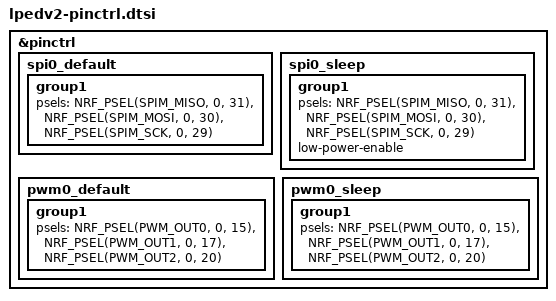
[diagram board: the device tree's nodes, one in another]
&pinctrl {
	spi0_default: spi0_default {
		group1 {
			psels = <NRF_PSEL(SPIM_MISO,	0, 	31)>,
					<NRF_PSEL(SPIM_MOSI, 	0, 	30)>,
					<NRF_PSEL(SPIM_SCK, 	0, 	29)>;
		};
	};

	spi0_sleep: spi0_sleep {
		group1 {
			psels = <NRF_PSEL(SPIM_MISO,	0, 	31)>,
					<NRF_PSEL(SPIM_MOSI, 	0, 	30)>,
					<NRF_PSEL(SPIM_SCK, 	0, 	29)>;
			low-power-enable;
		};
	};

	pwm0_default: pwm0_default {
		group1 {
			psels = <NRF_PSEL(PWM_OUT0, 0, 15)>,
					<NRF_PSEL(PWM_OUT1, 0, 17)>,
					<NRF_PSEL(PWM_OUT2, 0, 20)>;
		};
	};

	pwm0_sleep: pwm0_sleep {
		group1 {
			psels = <NRF_PSEL(PWM_OUT0, 0, 15)>,
					<NRF_PSEL(PWM_OUT1, 0, 17)>,
					<NRF_PSEL(PWM_OUT2, 0, 20)>;
		};
	};
};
